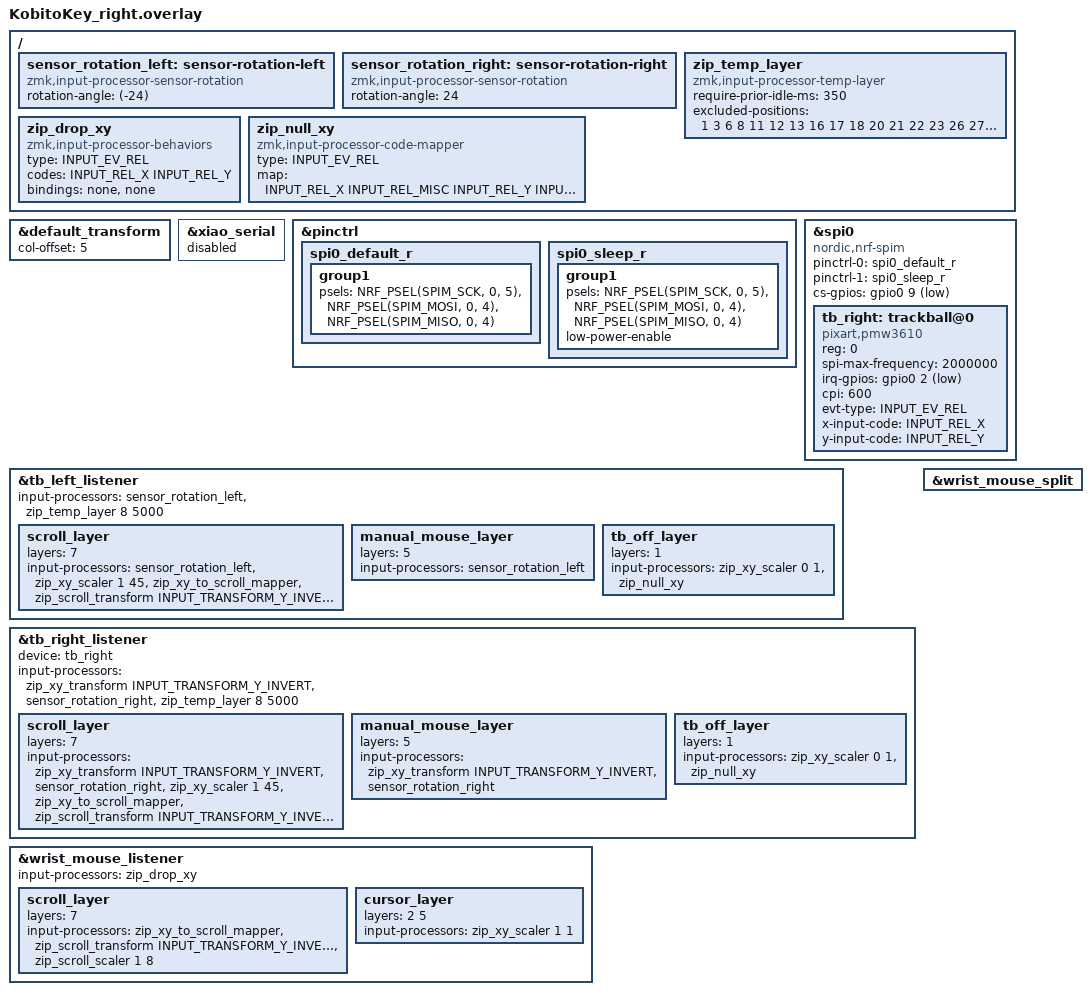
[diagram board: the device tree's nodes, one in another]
#include <zephyr/dt-bindings/pinctrl/nrf-pinctrl.h>
#include <zephyr/dt-bindings/input/input-event-codes.h>
#include <behaviors.dtsi>
#include "kobitokey.dtsi"
#include <input/processors.dtsi>
#include <input/processors/sensor_rotation.dtsi>

/* 右側マトリクスの列オフセット（5〜9列目） */
&default_transform { col-offset = <5>; };

&xiao_serial { status = "disabled"; };

&pinctrl {
    spi0_default_r: spi0_default_r {
        group1 {
            psels = <NRF_PSEL(SPIM_SCK,  0, 5)>,
                    <NRF_PSEL(SPIM_MOSI, 0, 4)>,
                    <NRF_PSEL(SPIM_MISO, 0, 4)>;
        };
    };
    spi0_sleep_r: spi0_sleep_r {
        group1 {
            psels = <NRF_PSEL(SPIM_SCK,  0, 5)>,
                    <NRF_PSEL(SPIM_MOSI, 0, 4)>,
                    <NRF_PSEL(SPIM_MISO, 0, 4)>;
            low-power-enable;
        };
    };
};

&spi0 {
    status = "okay";
    compatible = "nordic,nrf-spim";
    pinctrl-0 = <&spi0_default_r>;
    pinctrl-1 = <&spi0_sleep_r>;
    pinctrl-names = "default", "sleep";
    cs-gpios = <&gpio0 9 GPIO_ACTIVE_LOW>;

    tb_right: trackball@0 {
        status = "okay";
        compatible = "pixart,pmw3610";
        reg = <0>;
        spi-max-frequency = <2000000>;
        irq-gpios = <&gpio0 2 (GPIO_ACTIVE_LOW | GPIO_PULL_UP)>;
        cpi = <600>;

        evt-type = <INPUT_EV_REL>;
        x-input-code = <INPUT_REL_X>;
        y-input-code = <INPUT_REL_Y>;
    };
};

/ {
    sensor_rotation_left: sensor-rotation-left {
        compatible = "zmk,input-processor-sensor-rotation";
        status = "okay";
        #input-processor-cells = <0>;
        rotation-angle = <(-24)>;
    };

    sensor_rotation_right: sensor-rotation-right {
        compatible = "zmk,input-processor-sensor-rotation";
        #input-processor-cells = <0>;
        status = "okay";
        rotation-angle = <24>;
    };

    /omit-if-no-ref/ zip_temp_layer: zip_temp_layer {
        compatible = "zmk,input-processor-temp-layer";
        #input-processor-cells = <2>;
        require-prior-idle-ms = <350>;
    };

    /* base 用: wrist_mouse の通常時イベント破棄 */
    zip_drop_xy: zip_drop_xy {
        compatible = "zmk,input-processor-behaviors";
        #input-processor-cells = <0>;
        type = <INPUT_EV_REL>;
        codes = <INPUT_REL_X INPUT_REL_Y>;
        bindings = <&none &none>;
    };

    /*
     * layer_override 用: ZMK v0.3 の filter_with_input_config() は子ノード override 内で
     * ZMK_INPUT_PROC_STOP (1) を返しても 0 (CONTINUE) に丸める仕様のため、
     * スケーラで値を 0 にした上で未使用コード (INPUT_REL_MISC) へ退避し、移動とオートマウスを確実に遮断する
     */
    zip_null_xy: zip_null_xy {
        compatible = "zmk,input-processor-code-mapper";
        #input-processor-cells = <0>;
        type = <INPUT_EV_REL>;
        map = <INPUT_REL_X INPUT_REL_MISC INPUT_REL_Y INPUT_REL_MISC>;
    };
};

/* 左トラックボール（子機1 ID=0） */
&tb_left_listener {
    status = "okay";

    /* 通常時（トラボ自動検知ON）: カーソル操作 ＋ トラボ用オートマウス(Layer 8) */
    input-processors =
        <&sensor_rotation_left>,
        <&zip_temp_layer 8 5000>;

    /* 優先度1: Layer 7 (31または38を0.3秒以上長押し中) は上下左右ホイールスクロール */
    scroll_layer {
        layers = <7>;
        input-processors =
            <&sensor_rotation_left>,
            <&zip_xy_scaler 1 45>,
            <&zip_xy_to_scroll_mapper>,
            <&zip_scroll_transform INPUT_TRANSFORM_Y_INVERT>;
    };

    /* 優先度2: Layer 5 (32/37長押しによる手動マウスレイヤー中) はトラボ無効化中でもカーソル移動有効 */
    manual_mouse_layer {
        layers = <5>;
        input-processors =
            <&sensor_rotation_left>;
    };

    /* 優先度3: Layer 1 (12+13 / 16+17 トグルでトラボ無効化中) はカーソル移動もオートマウスも完全無効化 */
    tb_off_layer {
        layers = <1>;
        input-processors =
            <&zip_xy_scaler 0 1>,
            <&zip_null_xy>;
    };
};

/* 右トラックボール（親機ローカル接続） */
&tb_right_listener {
    status = "okay";
    device = <&tb_right>;

    /* 通常時（トラボ自動検知ON）: カーソル操作 ＋ トラボ用オートマウス(Layer 8) */
    input-processors =
        <&zip_xy_transform INPUT_TRANSFORM_Y_INVERT>,
        <&sensor_rotation_right>,
        <&zip_temp_layer 8 5000>;

    /* 優先度1: Layer 7 (31または38を0.3秒以上長押し中) は上下左右ホイールスクロール */
    scroll_layer {
        layers = <7>;
        input-processors =
            <&zip_xy_transform INPUT_TRANSFORM_Y_INVERT>,
            <&sensor_rotation_right>,
            <&zip_xy_scaler 1 45>,
            <&zip_xy_to_scroll_mapper>,
            <&zip_scroll_transform INPUT_TRANSFORM_Y_INVERT>;
    };

    /* 優先度2: Layer 5 (32/37長押しによる手動マウスレイヤー中) はトラボ無効化中でもカーソル移動有効 */
    manual_mouse_layer {
        layers = <5>;
        input-processors =
            <&zip_xy_transform INPUT_TRANSFORM_Y_INVERT>,
            <&sensor_rotation_right>;
    };

    /* 優先度3: Layer 1 (12+13 / 16+17 トグルでトラボ無効化中) はカーソル移動もオートマウスも完全無効化 */
    tb_off_layer {
        layers = <1>;
        input-processors =
            <&zip_xy_scaler 0 1>,
            <&zip_null_xy>;
    };
};

/* wrist_mouse（子機2 ID=1）: 親機側で split 受信を有効化 */
&wrist_mouse_split {
    status = "okay";
};

/* wrist_mouse（子機2 ID=1）:
 * - トグルOFF時: 通常は無反応、Layer 5 (32/37長押し) 中のみカーソル移動
 * - トグルON時 (Layer 2: 22+23 / 26+27): 常時カーソル移動（Layer 5中ももちろん有効）
 * - マウスレイヤー中に 31 または 38 を 0.3秒以上長押し (Layer 7) している間は上下左右ホイールスクロール
 */
&wrist_mouse_listener {
    status = "okay";

    /* 通常レイヤー(Layer 2 / 5 / 7 いずれも OFF)では完全無効化 */
    input-processors = <&zip_drop_xy>;

    /* 優先度1: Layer 7 (31または38を0.3秒以上長押し中) は上下左右ホイールスクロール */
    scroll_layer {
        layers = <7>;
        input-processors =
            <&zip_xy_to_scroll_mapper>,
            <&zip_scroll_transform INPUT_TRANSFORM_Y_INVERT>,
            <&zip_scroll_scaler 1 8>;
    };

    /* 優先度2: Layer 2 (常時ONトグル) または Layer 5 (32/37長押しマウスレイヤー) のいずれかが有効ならカーソル移動 */
    cursor_layer {
        layers = <2 5>;
        input-processors = <&zip_xy_scaler 1 1>;
    };
};

&zip_temp_layer {
    excluded-positions = <
        1
        3
        6
        8
        11
        12
        13
        16
        17
        18
        20
        21
        22
        23
        26
        27
        28
        29
        30
        31
        38
        39
    >;
};
